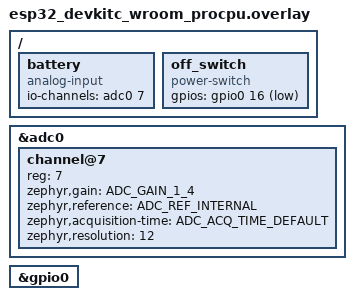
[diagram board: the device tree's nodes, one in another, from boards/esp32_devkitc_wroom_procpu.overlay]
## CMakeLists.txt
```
# SPDX-License-Identifier: Apache-2.0

cmake_minimum_required(VERSION 3.20.0)

set (CMAKE_CXX_STANDARD 20)
set (CMAKE_CXX_STANDARD_REQUIRED ON)

find_package(Zephyr REQUIRED HINTS $ENV{ZEPHYR_BASE})

# Include some zephyr cmake extensions
include(${ZEPHYR_BASE}/cmake/modules/extensions.cmake)

# Define board root to find our custom shield
set(BOARD_ROOT ${CMAKE_SOURCE_DIR})

# Add custom drivers directory
add_subdirectory(drivers)

#set(SHIELD kitronik_crb_5693)

project(gpscompass)

set(driver_sources "")
FILE(GLOB app_sources src/*.cpp)
target_sources(app PRIVATE ${app_sources} ${driver_sources})
```

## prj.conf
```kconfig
CONFIG_LOG=y
CONFIG_LOG_MODE_IMMEDIATE=y
CONFIG_LOG_BACKEND_UART=y

CONFIG_CPP=y
CONFIG_STD_CPP20=y
CONFIG_GLIBCXX_LIBCPP=y

CONFIG_I2C=y                                                                                         

CONFIG_CBPRINTF_FP_SUPPORT=y

CONFIG_ADC=y
CONFIG_GPIO=y
CONFIG_CONSOLE=y
CONFIG_SERIAL=y
```

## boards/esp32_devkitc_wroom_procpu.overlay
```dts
&adc0 {
	status = "okay";
	#address-cells = <1>;
	#size-cells = <0>;

	channel@7 {
		reg = <7>;
		zephyr,gain = "ADC_GAIN_1_4";
		zephyr,reference = "ADC_REF_INTERNAL";
		zephyr,acquisition-time = <ADC_ACQ_TIME_DEFAULT>;
		zephyr,resolution = <12>;
	};
};

&gpio0 {
	status = "okay";
};

/ {
    battery: battery {
        compatible = "analog-input";
        io-channels = <&adc0 7>;
        status = "okay";
    };

	off_switch: off_switch {
        compatible = "power-switch";
        gpios = <&gpio0 16 GPIO_ACTIVE_LOW>;
        status = "okay";
	};
};
```

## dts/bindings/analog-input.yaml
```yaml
description: |
    Analog input channel.

compatible: analog-input

include: base.yaml

properties:
    io-channels:
        type: phandle-array
        required: true
```

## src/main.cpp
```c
/*
 * Copyright (c) 2017 Intel Corporation
 *
 * SPDX-License-Identifier: Apache-2.0
 */

#include <zephyr/device.h>
#include <zephyr/drivers/adc.h>
#include <zephyr/drivers/gpio.h>
#include <zephyr/kernel.h>
#include <zephyr/logging/log.h>
LOG_MODULE_REGISTER(gpscompass);

#if !DT_NODE_EXISTS(DT_NODELABEL(battery))
#error "Battery voltage input not defined."
#endif

#if !DT_NODE_EXISTS(DT_NODELABEL(off_switch))
#error "Overlay for power off switch not properly defined."
#endif

static constexpr float battery_level_multiplier = 0.00203;
static const struct adc_dt_spec battery = ADC_DT_SPEC_GET(DT_NODELABEL(battery));
static const struct gpio_dt_spec off_switch = GPIO_DT_SPEC_GET(DT_NODELABEL(off_switch), gpios);


bool initialize_battery_level() {

  if (!adc_is_ready_dt(&battery)) {
    LOG_ERR("ADC device for battery level not ready");
    return false;
  }

  int ret = adc_channel_setup_dt(&battery);
  if (ret) {
    LOG_ERR("ADC channel setup for battery level failed: %d", ret);
    return false;
  }
  return true;
}

bool initialize_off_switch() {
  if (!gpio_is_ready_dt(&off_switch)) {
    LOG_ERR("GPIO not ready");
    return false;
  }

  int ret = gpio_pin_configure_dt(&off_switch, GPIO_DISCONNECTED);
  if (ret < 0) {
    LOG_ERR("Failed to configure offswitch to disconnected");
    return false;
  }
  return true;
}

float get_battery_level() {
  uint16_t sample;
  struct adc_sequence sequence = {
    .buffer = &sample,
    .buffer_size = sizeof(sample),
  };
  adc_sequence_init_dt(&battery, &sequence);
  int err = adc_read_dt(&battery, &sequence);
  if (err < 0) {
    LOG_ERR("Could not read: %d", err);
    return 0.0f;
  }
  int32_t val = static_cast<int32_t>(sample);
  err = adc_raw_to_millivolts_dt(&battery, &val);
  if (err < 0) {
    LOG_ERR("Failed to convert to millivolts: %d", err);
    return 0.0f;
  }
  float value = battery_level_multiplier * static_cast<float>(val);
  static float mean = value;
  mean = 0.9f * mean + 0.1f * value;
  return mean;
}

bool switch_off() {
  LOG_INF("Enabling output...");
  int ret = gpio_pin_configure_dt(&off_switch, GPIO_OUTPUT);
  if (ret < 0) {
    LOG_ERR("Failed to configure offswitch to output");
    return false;
  }
  LOG_INF("Switching off...");
  ret = gpio_pin_set_dt(&off_switch, GPIO_OUTPUT_ACTIVE);
  if (ret < 0) {
    LOG_ERR("Failed to switch off");
    return false;
  }
  LOG_INF("Switched off!");
  return true;
}

int main(void) {
  LOG_INF("GPS Compass initializing...");

  if (!initialize_battery_level()) return -1;
  if (!initialize_off_switch()) return -1;

  LOG_INF("GPS Compass running...");
  int i = 0;
  while (true) {

    k_sleep(K_MSEC(1000));
    auto battery_level = get_battery_level();
    LOG_INF("Battery: %f V", static_cast<double>(battery_level));
    if (battery_level < 3.5f) {
      LOG_WRN("Low Battery!");
      switch_off();
      k_fatal_halt(0);
    }
    ++i;
  }

  LOG_INF("GPS Compass done");
  return 0;
}
```

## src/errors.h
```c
#ifndef IMUBAR_ERRORS_H__
#define IMUBAR_ERRORS_H__

#include <zephyr/kernel.h>
#include <zephyr/sys/printk.h>
#include <zephyr/sys/reboot.h>

// We don't have user input so OK with non literal format strings
#pragma GCC diagnostic ignored "-Wformat-security"

template <typename... Args>
inline void error(int category, char const *const message, Args... args) {
  printk(message, args...);
  printk("\n");
  k_sleep(K_SECONDS(2));
  sys_reboot(SYS_REBOOT_COLD);
}

#endif
```
